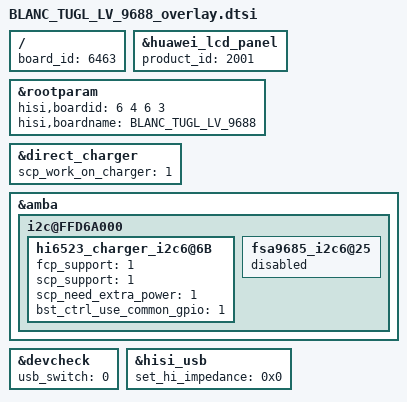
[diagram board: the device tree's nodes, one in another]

/**
 * Copyright (C) 2014 Hisilicon Ltd.
 *
 *  This program is free software; you can redistribute it and/or modify
 *  it under the terms of the GNU General Public License version 2 as
 *  publishhed by the Free Software Foundation.
 */

/include/ "BLANC_TUGL_LV_RF_overlay.dtsi"

/ {
	board_id = <6463>;
};

&huawei_lcd_panel {
	product_id = <2001>;
};

&rootparam {
    hisi,boardid = <6 4 6 3>;
    hisi,boardname = "BLANC_TUGL_LV_9688";
};


&direct_charger {
	scp_work_on_charger = <1>;
};
&amba {
	i2c@FFD6A000 {
		hi6523_charger_i2c6@6B{
			status = "ok";
			fcp_support = <1>;
			scp_support = <1>;
			scp_need_extra_power = <1>;
			bst_ctrl_use_common_gpio = <1>;
		};
		fsa9685_i2c6@25{
			status = "disabled";
		};
	};
};
&devcheck {
	usb_switch = <0>;
};
&hisi_usb {
	set_hi_impedance = <0x0>;
};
